# FSS_HYPERBUS1P0_0_HYPERBUS_CORE_0FC34000h register map
Vendor: Texas Instruments
Peripheral module from a debugger description file (folder AM275x).
Registers are 32-bit, access per field, reset 0x0 unless marked. A register's access mark holds for its fields unless they carry their own. Offsets are as the file gives them; lines under a group give offsets from that group; [hi:lo] are bit positions; {n}, {i} and the like mark numbered series; 'fields as' and 'values as' point back to an identical list; <NAME> marks a mode.

## hyperbus_core
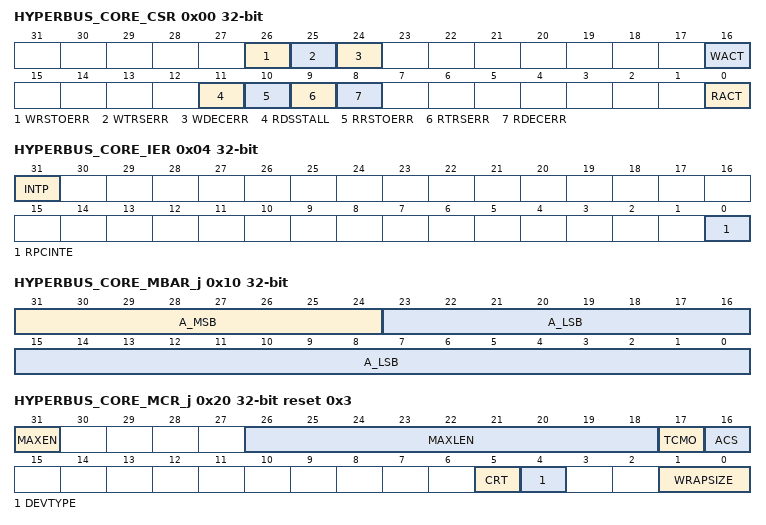
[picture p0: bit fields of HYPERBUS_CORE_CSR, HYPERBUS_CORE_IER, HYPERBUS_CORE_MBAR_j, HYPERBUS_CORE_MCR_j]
0x00 HYPERBUS_CORE_CSR ro — Controller Status Register to access the internal status of HyperBus Memory Controller IP
  [26] WRSTOERR — Write RSTO error. This bit indicates whether HyperBus memory is under reset state in the latest write operation.When this bit is set, HyperBus Memory Controller IP responds by AXI SLVERR.0-Normal operation,1- HyperBus memory is under reset Reset Source: mod_g_rst_n
  [25] WTRSERR — Write Transaction Error. This bit indicates whether AXI protocol is acceptable by HyperBus Memory Controller IP in the latest write transaction.When this bit is set, HyperBus Memory Controller IP responds by AXI SLVERR.0-Normal operation,1- This protocol is not supported Reset Source: mod_g_rst_n
  [24] WDECERR — Write Decode Error. This bit indicates whether access address is acceptable in the latest write transaction.When this bit is set, HyperBus Memory Controller IP responds by AXI DECERR.0-Normal operation. 1- Access address is not reachable Reset Source: mod_g_rst_n
  [16] WACT — Write is Active. This bit indicates whether write transaction is in progress or not.0- Write is idle,1 - Write is active.When receiving write request on write address channel, this bit becomes 1. When retrieving response signaling on write response channel, this bit becomes 0. Reset Source: mod_g_rst_n
  [11] RDSSTALL — RDS Stall. This bit indicates whether read data transfer from HyperBus memory is stalled [RDS remains LOW] in the latest read transaction.When this bit is set, HyperBus Memory Controller IP responds by AXI SLVERR. Reset Source: mod_g_rst_n
  [10] RRSTOERR — Read RSTO error. This bit indicates whether HyperBus memory is under reset state in the latest read operation.When this bit is set, HyperBus Memory Controller IP responds by AXI SLVERR.0 -Normal operation, 1 -HyperBus memory is under reset Reset Source: mod_g_rst_n
  [9] RTRSERR — Read Transaction Error. This bit indicates whether AXI protocol is acceptable by HyperBus Memory Controller IP in the latest read transaction.When this bit is set, HyperBus Memory Controller IP responds by AXI SLVERR.0- Normal operation,1- This protocol is not supported Reset Source: mod_g_rst_n
  [8] RDECERR — Read Decode Error. This bit indicates whether access address is acceptable in the latest read transaction.When this bit is set, HyperBus Memory Controller IP responds by AXI DECERR.0 -Normal operation,1- Access address is not reachable Reset Source: mod_g_rst_n
  [0] RACT — Read is Active. This bit indicates whether read transaction is in progress or not.0 - Read is idle, 1-Read is active. When receiving read request on read address channel, this bit becomes 1. When retrieving all requested data on read data channel, this bit becomes 0 Reset Source: mod_g_rst_n
0x04 HYPERBUS_CORE_IER — HyperBus Memory Controller IP outputs optional interrupt signal by condition enabled by this register
  [31] INTP rw — Interrupt Polarity Control. This bit is used to choose the polarity of optional interrupt signal [IENOn].0 -IENOn signal is active low.1 -IENOn signal is active high. [Reversed mode.] Reset Source: mod_g_rst_n
  [0] RPCINTE rw — HyperBus Memory Interrupt Enable.0 - Disable interrupt.1 - Enable interrupt by INT# signal of HyperBus memory. Reset Source: mod_g_rst_n
0x08 HYPERBUS_CORE_ISR ro — Interrupt status register
  [0] RPCINTS — HyperBus Memory Interrupt.0 -No interrupt.1 - This bit displays interrupt from INT# signal of HyperBus memory. Reset Source: mod_g_rst_n
0x10 HYPERBUS_CORE_MBAR_j — Memory Base Address Register for device connected to CS#
  [31:24] A_MSB rw — MSB 8 bit of the base address of addressable region to HyperBus memory Reset Source: mod_g_rst_n
  [23:0] A_LSB ro — Since register can be set in 16M bytes boundary, lower 24 bit is fixed to 0, if read, this field will always return 0 Reset Source: mod_g_rst_n
0x20 HYPERBUS_CORE_MCR_j reset 0x3 — Memory configuration register for CS#
  [31] MAXEN rw — Maximum length Enable0: No configurable CS# low time1: Configurable CS# low timeWhen this bit 1, CS# low time can be configurable by MAXLEN bit. Reset Source: mod_g_rst_n
  [26:18] MAXLEN rw — Maximum Length,This bit indicates maximum read/write transaction length to memory.This bit is ignored when MAXEN bit is 0.000000000: 2 Byte [1 HyperBus CK]000000001: 4 Byte [2 HyperBus CK]000000010: 6 Byte [3 HyperBus CK]111111111: 1024 Byte [512 HyperBus CK] Reset Source: mod_g_rst_n
  [17] TCMO rw — True Continuous Merge Option.0 : No merging WRAP and INCR.1 : Merging WRAP and INCR.Note that this function can be used with the HyperFlash with specific function. Please confirm whether it is corresponding HyperFlash before enabling this function.When HyperBus memory doesnt accept the 8-bit boundary address, and a wrapping burst access with ARSIZE=0 and ARADDR0=1 is used, this bit must not be set to 1. Reset Source: mod_g_rst_n
  [16] ACS rw — Asymmetry Cache Support.0 : No asymmetry cache system support.1 : Asymmetry cache system support.This function should be disabled if the HyperBus memory itself supports the asymmetry cache system. Reset Source: mod_g_rst_n
  [5] CRT rw — Configuration Register Target.0: Memory space1: CR space . This bit indicates whether the read or write operation accesses the memory or CR space. This bit is mapped to CA-46 bit in HyperRAM. When using HyperFlash, Reset Source: mod_g_rst_n
  [4] DEVTYPE rw — Device Type. 0: HyperFlash,1: HyperRAM. Device type for control target Reset Source: mod_g_rst_n
  [1:0] WRAPSIZE rw — Wrap Size.The wrap burst length of HyperBus memory. This bit is ignored when the asymmetry cache support bit is 0. When the asymmetry cache support is 1, this bit should be set the same as wrap size of configuration register in HyperBus memory.00 :Reserved.01 :64 Bytes.10 :16 Bytes.11 :32 Bytes. Reset Source: mod_g_rst_n
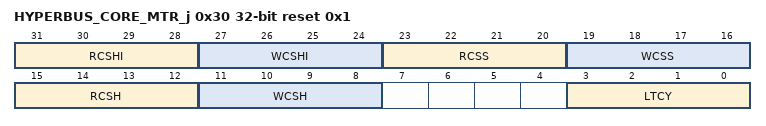
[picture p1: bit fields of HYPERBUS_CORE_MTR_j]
0x30 HYPERBUS_CORE_MTR_j reset 0x1 — CS# Memory Timing Register
  [31:28] RCSHI rw — Read Chip Select High Between Operations.This bit indicates CS# high time for read between operations. 0x0 corresponds to 1.5 clock cycle, 0xF corresponds to 16.5 clock cycle. Reset Source: mod_g_rst_n
  [27:24] WCSHI rw — Write Chip Select High Between Operations.This bit indicates CS# high time for write between operations. 0x0 corresponds to 1.5 clock cycle, 0xF corresponds to 16.5 clock cycle. Reset Source: mod_g_rst_n
  [23:20] RCSS rw — Read Chip Select Setup to next CK rising edge.This bit indicates CS# setup time for read from CS# assertion. 0x0 corresponds to 1 clock cycle, 0xF corresponds to 16 clock cycle. Reset Source: mod_g_rst_n
  [19:16] WCSS rw — Write Chip Select Setup to next CK rising edge.This bit indicates CS# setup time for write from CS# assertion. 0x0 corresponds to 1 clock cycle, 0xF corresponds to 16 clock cycle Reset Source: mod_g_rst_n
  [15:12] RCSH rw — Read Chip Select Hold after CK falling edge.This bit indicates CS# hold time for read to CS# de-assertion. 0x0 corresponds to 1 clock cycle, 0xF corresponds to 16 clock cycle. Reset Source: mod_g_rst_n
  [11:8] WCSH rw — Write Chip Select Hold after CK falling edge.This bit indicates CS# hold time for write to CS# de-assertion. 0x0 corresponds to 1 clock cycle, 0xF corresponding to 16 clock cycle Reset Source: mod_g_rst_n
  [3:0] LTCY rw — Latency Cycle. Only uses in HyperRAM.This bit indicates initial latency code for read/write access. This bit is ignored when MCRX.DEVTYPE is 0 [HyperFlash].0000 - 5 clock latency0001 - 6 clock latency0010 - Reserved1101 - Reserved1110 - 3 clock latency1111 - 4 clock latency Reset Source: mod_g_rst_n
0x40 HYPERBUS_CORE_GPOR — General Purpose Output Register
  [1:0] GPO rw — General Purpose Output interface.0: Output signal polarity is LOW.1: Output signal polarity is HIGH. Reset Source: mod_g_rst_n
0x44 HYPERBUS_CORE_WPR — Write Protection Register
  [0] WP rw — Write Protection Control. 0 : Not Protected. WP# signal is HIGH. 1 : Protected. WP# signal is LOW. Reset Source: mod_g_rst_n
0x48 HYPERBUS_CORE_LBR — Loop Back Register
  [0] LOOPBACK rw — The write transaction data written on AXI bus is looped back as the read data from RPC bus. The loop-back is performed between W DAT FIFO and R DAT FIFO in AXI interface controller. 0 :Disable loopback. 1 :Enable loopback. Reset Source: mod_g_rst_n
